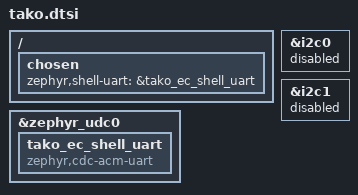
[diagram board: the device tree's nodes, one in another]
/*
 * Copyright (c) 2023 Sviatoslav Bulbakha
 *
 * SPDX-License-Identifier: MIT
 */

#include "tako-layouts.dtsi"
#include <zephyr/dt-bindings/pinctrl/nrf-pinctrl.h>
#include <zephyr/dt-bindings/gpio/gpio.h>

&i2c0 {
    status = "disabled";
};

&i2c1 {
    status = "disabled";
};

/*
 * nice!view SPI pins on nice!nano v2:
 *
 * MOSI = P1.01
 * SCK  = P1.02
 * CS   = P1.07
 */

/*
&pinctrl {
    nice_view_spi_default: nice_view_spi_default {
        group1 {
            psels = <NRF_PSEL(SPIM_MOSI, 1, 1)>,
                    <NRF_PSEL(SPIM_SCK, 1, 2)>;
        };
    };

    nice_view_spi_sleep: nice_view_spi_sleep {
        group1 {
            psels = <NRF_PSEL(SPIM_MOSI, 1, 1)>,
                    <NRF_PSEL(SPIM_SCK, 1, 2)>;
            low-power-enable;
        };
    };
};

&nice_view_spi {
    compatible = "nordic,nrf-spim";
    status = "okay";

    pinctrl-0 = <&nice_view_spi_default>;
    pinctrl-1 = <&nice_view_spi_sleep>;
    pinctrl-names = "default", "sleep";

    cs-gpios = <&gpio1 7 GPIO_ACTIVE_HIGH>;
};
*/

/* The generic analog calibrator enables the shell but supplies no USB overlay.
 * Give it its own CDC interface, while Studio runs on the dongle.
 */
/ {
    chosen {
        zephyr,shell-uart = &tako_ec_shell_uart;
    };
};

&zephyr_udc0 {
    tako_ec_shell_uart: tako_ec_shell_uart {
        compatible = "zephyr,cdc-acm-uart";
    };
};
